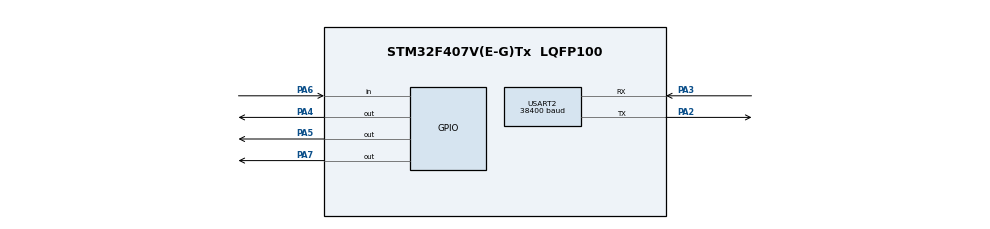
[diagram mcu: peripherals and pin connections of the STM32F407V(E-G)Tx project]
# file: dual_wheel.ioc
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IWDG.Prescaler=IWDG_PRESCALER_256
IWDG.Reload=1250
Mcu.Family=STM32F4
Mcu.Name=STM32F407V(E-G)Tx
Mcu.Package=LQFP100
NVIC.PriorityGroup=NVIC_PRIORITYGROUP_0
NVIC.USART2_IRQn=true\:0\:0\:false\:false\:true\:true\:true
PA13.Mode=Trace_Synchro_4bits_SW
PA13.Signal=SYS_JTMS-SWDIO
PA14.Mode=Trace_Synchro_4bits_SW
PA14.Signal=SYS_JTCK-SWCLK
PA2.Mode=Asynchronous
PA2.Signal=USART2_TX
PA3.Mode=Asynchronous
PA3.Signal=USART2_RX
PA4.Signal=GPIO_Output
PA5.Signal=GPIO_Output
PA6.Signal=GPIO_Input
PA7.Signal=GPIO_Output
PC14-OSC32_IN.Mode=LSE-External-Oscillator
PC14-OSC32_IN.Signal=RCC_OSC32_IN
PC15-OSC32_OUT.Mode=LSE-External-Oscillator
PC15-OSC32_OUT.Signal=RCC_OSC32_OUT
PE2.Mode=Trace_Synchro_4bits_SW
PE2.Signal=SYS_TRACECLK
PE3.Mode=Trace_Synchro_4bits_SW
PE3.Signal=SYS_TRACED0
PE4.Mode=Trace_Synchro_4bits_SW
PE4.Signal=SYS_TRACED1
PE5.Mode=Trace_Synchro_4bits_SW
PE5.Signal=SYS_TRACED2
PE6.Mode=Trace_Synchro_4bits_SW
PE6.Signal=SYS_TRACED3
PH0-OSC_IN.Mode=HSE-External-Oscillator
PH0-OSC_IN.Signal=RCC_OSC_IN
PH1-OSC_OUT.Mode=HSE-External-Oscillator
PH1-OSC_OUT.Signal=RCC_OSC_OUT
ProjectManager.HeapSize=0x200
ProjectManager.StackSize=0x400
ProjectManager.TargetToolchain=Makefile
RCC.48MHZClocksFreq_Value=48000000
RCC.AHBFreq_Value=168000000
RCC.APB1CLKDivider=RCC_HCLK_DIV4
RCC.APB1Freq_Value=42000000
RCC.APB1TimFreq_Value=84000000
RCC.APB2CLKDivider=RCC_HCLK_DIV4
RCC.APB2Freq_Value=42000000
RCC.APB2TimFreq_Value=84000000
RCC.CortexFreq_Value=168000000
RCC.HCLKFreq_Value=168000000
RCC.HSE_VALUE=8000000
RCC.HSI_VALUE=16000000
RCC.PLLM=4
RCC.PLLN=168
RCC.PLLQ=7
RCC.PLLSourceVirtual=RCC_PLLSOURCE_HSE
RCC.SYSCLKFreq_VALUE=168000000
RCC.SYSCLKSource=RCC_SYSCLKSOURCE_PLLCLK
RCC.VCOOutputFreq_Value=336000000
RTC.HourFormat=RTC_HOURFORMAT_12
USART2.BaudRate=38400
USART2.VirtualMode=VM_ASYNC
VP_IWDG_VS_IWDG.Mode=IWDG_Activate
VP_RTC_VS_RTC_Activate.Mode=RTC_Enabled
board=custom

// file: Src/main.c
/* USER CODE BEGIN Header */
/**
  ******************************************************************************
  * @file           : main.c
  * @brief          : Main program body
  ******************************************************************************
  * @attention
  *
  * <h2><center>&copy; Copyright (c) 2020 STMicroelectronics.
  * All rights reserved.</center></h2>
  *
  * This software component is licensed by ST under BSD 3-Clause license,
  * the "License"; You may not use this file except in compliance with the
  * License. You may obtain a copy of the License at:
  *                        opensource.org/licenses/BSD-3-Clause
  *
  ******************************************************************************
  */
/* USER CODE END Header */

#include "main.h"
#include "iwdg.h"
#include "rtc.h"
#include "usart.h"
#include "gpio.h"

/* USER CODE BEGIN Includes */
#include "sys_time.h"
#include "cl_log.h"
/* USER CODE END Includes */

/* USER CODE BEGIN PV */
/* Private variables ---------------------------------------------------------*/

/* USER CODE END PV */

void SystemClock_Config(void);
/* USER CODE BEGIN PFP */
/* Private function prototypes -----------------------------------------------*/

/* USER CODE END PFP */

int main(void)
{

  /* MCU Configuration--------------------------------------------------------*/

  /* Reset of all peripherals, Initializes the Flash interface and the Systick. */
  HAL_Init();

  /* Configure the system clock */
  SystemClock_Config();

  /* Initialize all configured peripherals */
  MX_GPIO_Init();
  MX_IWDG_Init();
  MX_USART2_UART_Init();
  MX_RTC_Init();

  /* Infinite loop */
  /* USER CODE BEGIN WHILE */
  LL_USART_EnableIT_RXNE(USART2);

  while (1)
  {
    IWDG_Process();
    /* USER CODE END WHILE */

    /* USER CODE BEGIN 3 */
    static uint64_t lastPrintTime = 0;
    if (TimeElapsed(lastPrintTime) > 1000)
    {
      SetToCurTime(&lastPrintTime);

      CL_LOG_LINE("%lus", (uint32_t)(GetSysTime() / 1000));
    }
  }
  /* USER CODE END 3 */
}

void SystemClock_Config(void)
{
  LL_FLASH_SetLatency(LL_FLASH_LATENCY_5);

  if (LL_FLASH_GetLatency() != LL_FLASH_LATENCY_5)
  {
    Error_Handler();
  }
  LL_PWR_SetRegulVoltageScaling(LL_PWR_REGU_VOLTAGE_SCALE1);
  LL_RCC_HSE_Enable();

  /* Wait till HSE is ready */
  while (LL_RCC_HSE_IsReady() != 1)
  {
  }
  LL_RCC_LSI_Enable();

  /* Wait till LSI is ready */
  while (LL_RCC_LSI_IsReady() != 1)
  {
  }
  LL_PWR_EnableBkUpAccess();
  LL_RCC_ForceBackupDomainReset();
  LL_RCC_ReleaseBackupDomainReset();
  LL_RCC_SetRTCClockSource(LL_RCC_RTC_CLKSOURCE_LSI);
  LL_RCC_EnableRTC();
  LL_RCC_PLL_ConfigDomain_SYS(LL_RCC_PLLSOURCE_HSE, LL_RCC_PLLM_DIV_4, 168, LL_RCC_PLLP_DIV_2);
  LL_RCC_PLL_Enable();

  /* Wait till PLL is ready */
  while (LL_RCC_PLL_IsReady() != 1)
  {
  }
  LL_RCC_SetAHBPrescaler(LL_RCC_SYSCLK_DIV_1);
  LL_RCC_SetAPB1Prescaler(LL_RCC_APB1_DIV_4);
  LL_RCC_SetAPB2Prescaler(LL_RCC_APB2_DIV_4);
  LL_RCC_SetSysClkSource(LL_RCC_SYS_CLKSOURCE_PLL);

  /* Wait till System clock is ready */
  while (LL_RCC_GetSysClkSource() != LL_RCC_SYS_CLKSOURCE_STATUS_PLL)
  {
  }
  LL_SetSystemCoreClock(168000000);

  /* Update the time base */
  if (HAL_InitTick(TICK_INT_PRIORITY) != HAL_OK)
  {
    Error_Handler();
  };
}

void Error_Handler(void)
{
  while (1)
  {
  }
}

/************************ (C) COPYRIGHT STMicroelectronics *****END OF FILE****/
